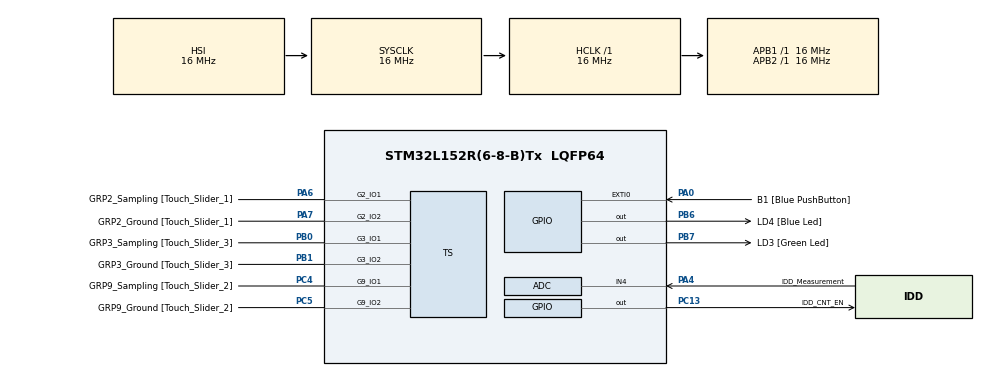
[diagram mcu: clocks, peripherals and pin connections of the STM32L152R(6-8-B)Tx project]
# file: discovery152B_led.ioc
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ADC.Channel=ADC_CHANNEL_4
ADC.Channel-0\#ChannelRegularConversion=ADC_CHANNEL_4
ADC.Channel-IN4=ADC_CHANNEL_4
ADC.ExternalTrigConv=ADC_EXTERNALTRIGCONV_T2_CC3
ADC.ExternalTrigConv-0\#ChannelRegularConversion=ADC_SOFTWARE_START
ADC.ExternalTrigConvEdge=ADC_EXTERNALTRIGCONVEDGE_RISING
ADC.Rank-0\#ChannelRegularConversion=1
ADC.SamplingTime-0\#ChannelRegularConversion=ADC_SAMPLETIME_4CYCLES
Dma.MEMTOMEM.0.Direction=DMA_MEMORY_TO_MEMORY
Dma.MEMTOMEM.0.Instance=DMA1_Channel1
Dma.MEMTOMEM.0.MemDataAlignment=DMA_MDATAALIGN_BYTE
Dma.MEMTOMEM.0.MemInc=DMA_MINC_ENABLE
Dma.MEMTOMEM.0.Mode=DMA_NORMAL
Dma.MEMTOMEM.0.PeriphDataAlignment=DMA_PDATAALIGN_BYTE
Dma.MEMTOMEM.0.PeriphInc=DMA_PINC_ENABLE
Dma.MEMTOMEM.0.Priority=DMA_PRIORITY_LOW
Dma.Request0=MEMTOMEM
Mcu.Family=STM32L1
Mcu.Name=STM32L152R(6-8-B)Tx
Mcu.Package=LQFP64
NVIC.PriorityGroup=NVIC_PRIORITYGROUP_0
PA0-WKUP1.GPIO_Label=B1 [Blue PushButton]
PA0-WKUP1.GPIO_ModeDefaultEXTI=GPIO_MODE_EVT_RISING
PA0-WKUP1.GPIO_PuPd=GPIO_NOPULL
PA0-WKUP1.Signal=GPXTI0
PA1.GPIO_Label=SEG0 [GH08172T_SEG0]
PA1.GPIO_Mode=GPIO_MODE_AF_PP
PA1.GPIO_PuPd=GPIO_NOPULL
PA1.GPIO_Speed=GPIO_SPEED_FREQ_LOW
PA1.Signal=LCD_SEG0
PA10.GPIO_Label=COM2 [GH08172T_COM2]
PA10.GPIO_Mode=GPIO_MODE_AF_PP
PA10.GPIO_PuPd=GPIO_NOPULL
PA10.GPIO_Speed=GPIO_SPEED_FREQ_LOW
PA10.Signal=LCD_COM2
PA13.GPIO_Label=SWDIO
PA13.Mode=Serial_Wire
PA13.Signal=SYS_JTMS-SWDIO
PA14.GPIO_Label=SWCLK
PA14.Mode=Serial_Wire
PA14.Signal=SYS_JTCK-SWCLK
PA15.GPIO_Label=SEG12 [GH08172T_SEG12]
PA15.GPIO_Mode=GPIO_MODE_AF_PP
PA15.GPIO_PuPd=GPIO_NOPULL
PA15.GPIO_Speed=GPIO_SPEED_FREQ_LOW
PA15.Signal=LCD_SEG17
PA2.GPIO_Label=SEG1 [GH08172T_SEG1]
PA2.GPIO_Mode=GPIO_MODE_AF_PP
PA2.GPIO_PuPd=GPIO_NOPULL
PA2.GPIO_Speed=GPIO_SPEED_FREQ_LOW
PA2.Signal=LCD_SEG1
PA3.GPIO_Label=SEG2 [GH08172T_SEG2]
PA3.GPIO_Mode=GPIO_MODE_AF_PP
PA3.GPIO_PuPd=GPIO_NOPULL
PA3.GPIO_Speed=GPIO_SPEED_FREQ_LOW
PA3.Signal=LCD_SEG2
PA4.GPIO_Label=IDD_Measurement
PA4.GPIO_Mode=GPIO_MODE_ANALOG
PA4.GPIO_PuPd=GPIO_NOPULL
PA4.Mode=IN4
PA4.Signal=ADC_IN4
PA6.GPIO_Label=GRP2_Sampling [Touch_Slider_1]
PA6.Mode=G2_IO1-Sampling
PA6.Signal=TS_G2_IO1
PA7.GPIO_Label=GRP2_Ground [Touch_Slider_1]
PA7.Mode=G2_IO2-Channel
PA7.Signal=TS_G2_IO2
PA8.GPIO_Label=COM0 [GH08172T_COM0]
PA8.GPIO_Mode=GPIO_MODE_AF_PP
PA8.GPIO_PuPd=GPIO_NOPULL
PA8.GPIO_Speed=GPIO_SPEED_FREQ_LOW
PA8.Signal=LCD_COM0
PA9.GPIO_Label=COM1 [GH08172T_COM1]
PA9.GPIO_Mode=GPIO_MODE_AF_PP
PA9.GPIO_PuPd=GPIO_NOPULL
PA9.GPIO_Speed=GPIO_SPEED_FREQ_LOW
PA9.Signal=LCD_COM1
PB0.GPIO_Label=GRP3_Sampling [Touch_Slider_3]
PB0.Mode=G3_IO1-Sampling
PB0.Signal=TS_G3_IO1
PB1.GPIO_Label=GRP3_Ground [Touch_Slider_3]
PB1.Mode=G3_IO2-Channel
PB1.Signal=TS_G3_IO2
PB10.GPIO_Label=SEG6 [GH08172T_SEG6]
PB10.GPIO_Mode=GPIO_MODE_AF_PP
PB10.GPIO_PuPd=GPIO_NOPULL
PB10.GPIO_Speed=GPIO_SPEED_FREQ_LOW
PB10.Signal=LCD_SEG10
PB11.GPIO_Label=SEG7 [GH08172T_SEG7]
PB11.GPIO_Mode=GPIO_MODE_AF_PP
PB11.GPIO_PuPd=GPIO_NOPULL
PB11.GPIO_Speed=GPIO_SPEED_FREQ_LOW
PB11.Signal=LCD_SEG11
PB12.GPIO_Label=SEG8 [GH08172T_SEG8]
PB12.GPIO_Mode=GPIO_MODE_AF_PP
PB12.GPIO_PuPd=GPIO_NOPULL
PB12.GPIO_Speed=GPIO_SPEED_FREQ_LOW
PB12.Signal=LCD_SEG12
PB13.GPIO_Label=SEG9 [GH08172T_SEG9]
PB13.GPIO_Mode=GPIO_MODE_AF_PP
PB13.GPIO_PuPd=GPIO_NOPULL
PB13.GPIO_Speed=GPIO_SPEED_FREQ_LOW
PB13.Signal=LCD_SEG13
PB14.GPIO_Label=SEG10 [GH08172T_SEG10]
PB14.GPIO_Mode=GPIO_MODE_AF_PP
PB14.GPIO_PuPd=GPIO_NOPULL
PB14.GPIO_Speed=GPIO_SPEED_FREQ_LOW
PB14.Signal=LCD_SEG14
PB15.GPIO_Label=SEG11 [GH08172T_SEG11]
PB15.GPIO_Mode=GPIO_MODE_AF_PP
PB15.GPIO_PuPd=GPIO_NOPULL
PB15.GPIO_Speed=GPIO_SPEED_FREQ_LOW
PB15.Signal=LCD_SEG15
PB3.GPIO_Label=SEG3 [GH08172T_SEG3]
PB3.GPIO_Mode=GPIO_MODE_AF_PP
PB3.GPIO_PuPd=GPIO_NOPULL
PB3.GPIO_Speed=GPIO_SPEED_FREQ_LOW
PB3.Signal=LCD_SEG7
PB4.GPIO_Label=SEG4 [GH08172T_SEG4]
PB4.GPIO_Mode=GPIO_MODE_AF_PP
PB4.GPIO_PuPd=GPIO_NOPULL
PB4.GPIO_Speed=GPIO_SPEED_FREQ_LOW
PB4.Signal=LCD_SEG8
PB5.GPIO_Label=SEG5 [GH08172T_SEG5]
PB5.GPIO_Mode=GPIO_MODE_AF_PP
PB5.GPIO_PuPd=GPIO_NOPULL
PB5.GPIO_Speed=GPIO_SPEED_FREQ_LOW
PB5.Signal=LCD_SEG9
PB6.GPIO_Label=LD4 [Blue Led]
PB6.GPIO_ModeDefaultOutputPP=GPIO_MODE_OUTPUT_PP
PB6.GPIO_PuPd=GPIO_NOPULL
PB6.GPIO_Speed=GPIO_SPEED_FREQ_LOW
PB6.Signal=GPIO_Output
PB7.GPIO_Label=LD3 [Green Led]
PB7.GPIO_ModeDefaultOutputPP=GPIO_MODE_OUTPUT_PP
PB7.GPIO_PuPd=GPIO_NOPULL
PB7.GPIO_Speed=GPIO_SPEED_FREQ_LOW
PB7.Signal=GPIO_Output
PB8.GPIO_Label=SEG13 [GH08172T_SEG13]
PB8.GPIO_Mode=GPIO_MODE_AF_PP
PB8.GPIO_PuPd=GPIO_NOPULL
PB8.GPIO_Speed=GPIO_SPEED_FREQ_LOW
PB8.Signal=LCD_SEG16
PB9.GPIO_Label=COM3 [GH08172T_COM3]
PB9.GPIO_Mode=GPIO_MODE_AF_PP
PB9.GPIO_PuPd=GPIO_NOPULL
PB9.GPIO_Speed=GPIO_SPEED_FREQ_LOW
PB9.Signal=LCD_COM3
PC0.GPIO_Label=SEG14 [GH08172T_SEG14]
PC0.GPIO_Mode=GPIO_MODE_AF_PP
PC0.GPIO_PuPd=GPIO_NOPULL
PC0.GPIO_Speed=GPIO_SPEED_FREQ_LOW
PC0.Signal=LCD_SEG18
PC1.GPIO_Label=SEG15 [GH08172T_SEG15]
PC1.GPIO_Mode=GPIO_MODE_AF_PP
PC1.GPIO_PuPd=GPIO_NOPULL
PC1.GPIO_Speed=GPIO_SPEED_FREQ_LOW
PC1.Signal=LCD_SEG19
PC10.GPIO_Label=SEG22 [GH08172T_SEG22]
PC10.GPIO_Mode=GPIO_MODE_AF_PP
PC10.GPIO_PuPd=GPIO_NOPULL
PC10.GPIO_Speed=GPIO_SPEED_FREQ_LOW
PC10.Signal=LCD_SEG28
PC11.GPIO_Label=SEG23 [GH08172T_SEG23]
PC11.GPIO_Mode=GPIO_MODE_AF_PP
PC11.GPIO_PuPd=GPIO_NOPULL
PC11.GPIO_Speed=GPIO_SPEED_FREQ_LOW
PC11.Signal=LCD_SEG29
PC13-WKUP2.GPIO_Label=IDD_CNT_EN
PC13-WKUP2.Signal=GPIO_Output
PC14-OSC32_IN.GPIO_Label=PC14-OSC32_IN
PC14-OSC32_IN.Mode=LSE-External-Oscillator
PC14-OSC32_IN.Signal=RCC_OSC32_IN
PC15-OSC32_OUT.GPIO_Label=PC15-OSC32_OUT
PC15-OSC32_OUT.Mode=LSE-External-Oscillator
PC15-OSC32_OUT.Signal=RCC_OSC32_OUT
PC2.GPIO_Label=SEG16 [GH08172T_SEG16]
PC2.GPIO_Mode=GPIO_MODE_AF_PP
PC2.GPIO_PuPd=GPIO_NOPULL
PC2.GPIO_Speed=GPIO_SPEED_FREQ_LOW
PC2.Signal=LCD_SEG20
PC3.GPIO_Label=SEG17 [GH08172T_SEG17]
PC3.GPIO_Mode=GPIO_MODE_AF_PP
PC3.GPIO_PuPd=GPIO_NOPULL
PC3.GPIO_Speed=GPIO_SPEED_FREQ_LOW
PC3.Signal=LCD_SEG21
PC4.GPIO_Label=GRP9_Sampling [Touch_Slider_2]
PC4.Mode=G9_IO1-Sampling
PC4.Signal=TS_G9_IO1
PC5.GPIO_Label=GRP9_Ground [Touch_Slider_2]
PC5.Mode=G9_IO2-Channel
PC5.Signal=TS_G9_IO2
PC6.GPIO_Label=SEG18 [GH08172T_SEG18]
PC6.GPIO_Mode=GPIO_MODE_AF_PP
PC6.GPIO_PuPd=GPIO_NOPULL
PC6.GPIO_Speed=GPIO_SPEED_FREQ_LOW
PC6.Signal=LCD_SEG24
PC7.GPIO_Label=SEG19 [GH08172T_SEG19]
PC7.GPIO_Mode=GPIO_MODE_AF_PP
PC7.GPIO_PuPd=GPIO_NOPULL
PC7.GPIO_Speed=GPIO_SPEED_FREQ_LOW
PC7.Signal=LCD_SEG25
PC8.GPIO_Label=SEG20 [GH08172T_SEG20]
PC8.GPIO_Mode=GPIO_MODE_AF_PP
PC8.GPIO_PuPd=GPIO_NOPULL
PC8.GPIO_Speed=GPIO_SPEED_FREQ_LOW
PC8.Signal=LCD_SEG26
PC9.GPIO_Label=SEG21 [GH08172T_SEG21]
PC9.GPIO_Mode=GPIO_MODE_AF_PP
PC9.GPIO_PuPd=GPIO_NOPULL
PC9.GPIO_Speed=GPIO_SPEED_FREQ_LOW
PC9.Signal=LCD_SEG27
PH0-OSC_IN.Mode=HSE-External-Oscillator
PH0-OSC_IN.Signal=RCC_OSC_IN
PH1-OSC_OUT.Mode=HSE-External-Oscillator
PH1-OSC_OUT.Signal=RCC_OSC_OUT
ProjectManager.HeapSize=0x200
ProjectManager.StackSize=0x400
ProjectManager.TargetToolchain=Makefile
RCC.48MHZClocksFreq_Value=48000000
RCC.AHBFreq_Value=16000000
RCC.APB1Freq_Value=16000000
RCC.APB1TimFreq_Value=16000000
RCC.APB2Freq_Value=16000000
RCC.APB2TimFreq_Value=16000000
RCC.HCLKFreq_Value=16000000
RCC.HSE_VALUE=8000000
RCC.HSI_VALUE=16000000
RCC.MSI_VALUE=2097000
RCC.PLLDIV=RCC_PLL_DIV3
RCC.PLLMUL=RCC_PLL_MUL6
RCC.RTCClockSelectionVirtual=RCC_RTCCLKSOURCE_LSE
RCC.SYSCLKFreq_VALUE=16000000
RCC.SYSCLKSource=RCC_SYSCLKSOURCE_HSI
RCC.USBOutput=48000000
RCC.VCOOutputFreq_Value=96000000
TS.SamplingIOs-G2_IO1-Sampling=TSC_GROUP2_IO1
TS.SamplingIOs-G3_IO1-Sampling=TSC_GROUP3_IO1
TS.SamplingIOs-G9_IO1-Sampling=TSC_GROUP9_IO1
board=STM32L-DISCOVERY

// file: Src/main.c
/* USER CODE BEGIN Header */
/**
  ******************************************************************************
  * @file           : main.c
  * @brief          : Main program body
  ******************************************************************************
  * @attention
  *
  * <h2><center>&copy; Copyright (c) 2020 STMicroelectronics.
  * All rights reserved.</center></h2>
  *
  * This software component is licensed by ST under BSD 3-Clause license,
  * the "License"; You may not use this file except in compliance with the
  * License. You may obtain a copy of the License at:
  *                        opensource.org/licenses/BSD-3-Clause
  *
  ******************************************************************************
  */
/* USER CODE END Header */

#include "main.h"

ADC_HandleTypeDef hadc;

DMA_HandleTypeDef hdma_memtomem_dma1_channel1;
/* USER CODE BEGIN PV */

static uint8_t ToggleLed;
/* USER CODE END PV */

void SystemClock_Config(void);
static void MX_GPIO_Init(void);
static void MX_DMA_Init(void);
static void MX_ADC_Init(void);
static void MX_TS_Init(void);
/* USER CODE BEGIN PFP */
void LED_ChangeRealize(void);
/* USER CODE END PFP */

/* USER CODE BEGIN 0 */

void LED_SetToChange(void)
{
    ToggleLed = 1;

}
void LED_ChangeRealize(void)
{

      HAL_GPIO_TogglePin(LD4_GPIO_Port, LD4_Pin);
      HAL_GPIO_TogglePin(LD3_GPIO_Port, LD3_Pin);
      ToggleLed=0;

}
/* USER CODE END 0 */

int main(void)
{

  /* MCU Configuration--------------------------------------------------------*/

  /* Reset of all peripherals, Initializes the Flash interface and the Systick. */
  HAL_Init();

  /* Configure the system clock */
  SystemClock_Config();

  /* Initialize all configured peripherals */
  MX_GPIO_Init();
  MX_DMA_Init();
  MX_ADC_Init();
  MX_TS_Init();

  /* Infinite loop */
  /* USER CODE BEGIN WHILE */
 HAL_GPIO_WritePin(LD4_GPIO_Port,LD4_Pin, GPIO_PIN_SET);
 HAL_GPIO_WritePin(LD3_GPIO_Port,LD3_Pin, GPIO_PIN_RESET);
  while (1)
  {
    /* USER CODE END WHILE */
      if (ToggleLed)
          LED_ChangeRealize();

  }
}

void SystemClock_Config(void)
{
  RCC_OscInitTypeDef RCC_OscInitStruct = {0};
  RCC_ClkInitTypeDef RCC_ClkInitStruct = {0};

  /** Configure the main internal regulator output voltage
  */
  __HAL_PWR_VOLTAGESCALING_CONFIG(PWR_REGULATOR_VOLTAGE_SCALE1);
  /** Initializes the CPU, AHB and APB busses clocks
  */
  RCC_OscInitStruct.OscillatorType = RCC_OSCILLATORTYPE_HSI;
  RCC_OscInitStruct.HSIState = RCC_HSI_ON;
  RCC_OscInitStruct.HSICalibrationValue = RCC_HSICALIBRATION_DEFAULT;
  RCC_OscInitStruct.PLL.PLLState = RCC_PLL_NONE;
  if (HAL_RCC_OscConfig(&RCC_OscInitStruct) != HAL_OK)
  {
    Error_Handler();
  }
  /** Initializes the CPU, AHB and APB busses clocks
  */
  RCC_ClkInitStruct.ClockType = RCC_CLOCKTYPE_HCLK|RCC_CLOCKTYPE_SYSCLK
                              |RCC_CLOCKTYPE_PCLK1|RCC_CLOCKTYPE_PCLK2;
  RCC_ClkInitStruct.SYSCLKSource = RCC_SYSCLKSOURCE_HSI;
  RCC_ClkInitStruct.AHBCLKDivider = RCC_SYSCLK_DIV1;
  RCC_ClkInitStruct.APB1CLKDivider = RCC_HCLK_DIV1;
  RCC_ClkInitStruct.APB2CLKDivider = RCC_HCLK_DIV1;

  if (HAL_RCC_ClockConfig(&RCC_ClkInitStruct, FLASH_LATENCY_0) != HAL_OK)
  {
    Error_Handler();
  }
}

static void MX_ADC_Init(void)
{

  ADC_ChannelConfTypeDef sConfig = {0};

  /** Configure the global features of the ADC (Clock, Resolution, Data Alignment and number of conversion)
  */
  hadc.Instance = ADC1;
  hadc.Init.ClockPrescaler = ADC_CLOCK_ASYNC_DIV1;
  hadc.Init.Resolution = ADC_RESOLUTION_12B;
  hadc.Init.DataAlign = ADC_DATAALIGN_RIGHT;
  hadc.Init.ScanConvMode = ADC_SCAN_DISABLE;
  hadc.Init.EOCSelection = ADC_EOC_SEQ_CONV;
  hadc.Init.LowPowerAutoWait = ADC_AUTOWAIT_DISABLE;
  hadc.Init.LowPowerAutoPowerOff = ADC_AUTOPOWEROFF_DISABLE;
  hadc.Init.ChannelsBank = ADC_CHANNELS_BANK_A;
  hadc.Init.ContinuousConvMode = DISABLE;
  hadc.Init.NbrOfConversion = 1;
  hadc.Init.DiscontinuousConvMode = DISABLE;
  hadc.Init.ExternalTrigConv = ADC_EXTERNALTRIGCONV_T2_CC3;
  hadc.Init.ExternalTrigConvEdge = ADC_EXTERNALTRIGCONVEDGE_RISING;
  hadc.Init.DMAContinuousRequests = DISABLE;
  if (HAL_ADC_Init(&hadc) != HAL_OK)
  {
    Error_Handler();
  }
  /** Configure for the selected ADC regular channel its corresponding rank in the sequencer and its sample time.
  */
  sConfig.Channel = ADC_CHANNEL_4;
  sConfig.Rank = ADC_REGULAR_RANK_1;
  sConfig.SamplingTime = ADC_SAMPLETIME_4CYCLES;
  if (HAL_ADC_ConfigChannel(&hadc, &sConfig) != HAL_OK)
  {
    Error_Handler();
  }

}

static void MX_TS_Init(void)
{

}

static void MX_DMA_Init(void)
{

  /* DMA controller clock enable */
  __HAL_RCC_DMA1_CLK_ENABLE();

  /* Configure DMA request hdma_memtomem_dma1_channel1 on DMA1_Channel1 */
  hdma_memtomem_dma1_channel1.Instance = DMA1_Channel1;
  hdma_memtomem_dma1_channel1.Init.Direction = DMA_MEMORY_TO_MEMORY;
  hdma_memtomem_dma1_channel1.Init.PeriphInc = DMA_PINC_ENABLE;
  hdma_memtomem_dma1_channel1.Init.MemInc = DMA_MINC_ENABLE;
  hdma_memtomem_dma1_channel1.Init.PeriphDataAlignment = DMA_PDATAALIGN_BYTE;
  hdma_memtomem_dma1_channel1.Init.MemDataAlignment = DMA_MDATAALIGN_BYTE;
  hdma_memtomem_dma1_channel1.Init.Mode = DMA_NORMAL;
  hdma_memtomem_dma1_channel1.Init.Priority = DMA_PRIORITY_LOW;
  if (HAL_DMA_Init(&hdma_memtomem_dma1_channel1) != HAL_OK)
  {
    Error_Handler( );
  }

}

static void MX_GPIO_Init(void)
{
  GPIO_InitTypeDef GPIO_InitStruct = {0};

  /* GPIO Ports Clock Enable */
  __HAL_RCC_GPIOC_CLK_ENABLE();
  __HAL_RCC_GPIOH_CLK_ENABLE();
  __HAL_RCC_GPIOA_CLK_ENABLE();
  __HAL_RCC_GPIOB_CLK_ENABLE();

  /*Configure GPIO pin Output Level */
  HAL_GPIO_WritePin(IDD_CNT_EN_GPIO_Port, IDD_CNT_EN_Pin, GPIO_PIN_RESET);

  /*Configure GPIO pin Output Level */
  HAL_GPIO_WritePin(GPIOB, LD4_Pin|LD3_Pin, GPIO_PIN_RESET);

  /*Configure GPIO pin : IDD_CNT_EN_Pin */
  GPIO_InitStruct.Pin = IDD_CNT_EN_Pin;
  GPIO_InitStruct.Mode = GPIO_MODE_OUTPUT_PP;
  GPIO_InitStruct.Pull = GPIO_NOPULL;
  GPIO_InitStruct.Speed = GPIO_SPEED_FREQ_LOW;
  HAL_GPIO_Init(IDD_CNT_EN_GPIO_Port, &GPIO_InitStruct);

  /*Configure GPIO pins : SEG14_Pin SEG15_Pin SEG16_Pin SEG17_Pin
                           SEG18_Pin SEG19_Pin SEG20_Pin SEG21_Pin
                           SEG22_Pin SEG23_Pin */
  GPIO_InitStruct.Pin = SEG14_Pin|SEG15_Pin|SEG16_Pin|SEG17_Pin
                          |SEG18_Pin|SEG19_Pin|SEG20_Pin|SEG21_Pin
                          |SEG22_Pin|SEG23_Pin;
  GPIO_InitStruct.Mode = GPIO_MODE_AF_PP;
  GPIO_InitStruct.Pull = GPIO_NOPULL;
  GPIO_InitStruct.Speed = GPIO_SPEED_FREQ_LOW;
  GPIO_InitStruct.Alternate = GPIO_AF11_LCD;
  HAL_GPIO_Init(GPIOC, &GPIO_InitStruct);

  /*Configure GPIO pin : B1_Pin */
  GPIO_InitStruct.Pin = B1_Pin;
  GPIO_InitStruct.Mode = GPIO_MODE_EVT_RISING;
  GPIO_InitStruct.Pull = GPIO_NOPULL;
  HAL_GPIO_Init(B1_GPIO_Port, &GPIO_InitStruct);

  /*Configure GPIO pins : SEG0_Pin SEG1_Pin SEG2_Pin COM0_Pin
                           COM1_Pin COM2_Pin SEG12_Pin */
  GPIO_InitStruct.Pin = SEG0_Pin|SEG1_Pin|SEG2_Pin|COM0_Pin
                          |COM1_Pin|COM2_Pin|SEG12_Pin;
  GPIO_InitStruct.Mode = GPIO_MODE_AF_PP;
  GPIO_InitStruct.Pull = GPIO_NOPULL;
  GPIO_InitStruct.Speed = GPIO_SPEED_FREQ_LOW;
  GPIO_InitStruct.Alternate = GPIO_AF11_LCD;
  HAL_GPIO_Init(GPIOA, &GPIO_InitStruct);

  /*Configure GPIO pins : SEG6_Pin SEG7_Pin SEG8_Pin SEG9_Pin
                           SEG10_Pin SEG11_Pin SEG3_Pin SEG4_Pin
                           SEG5_Pin SEG13_Pin COM3_Pin */
  GPIO_InitStruct.Pin = SEG6_Pin|SEG7_Pin|SEG8_Pin|SEG9_Pin
                          |SEG10_Pin|SEG11_Pin|SEG3_Pin|SEG4_Pin
                          |SEG5_Pin|SEG13_Pin|COM3_Pin;
  GPIO_InitStruct.Mode = GPIO_MODE_AF_PP;
  GPIO_InitStruct.Pull = GPIO_NOPULL;
  GPIO_InitStruct.Speed = GPIO_SPEED_FREQ_LOW;
  GPIO_InitStruct.Alternate = GPIO_AF11_LCD;
  HAL_GPIO_Init(GPIOB, &GPIO_InitStruct);

  /*Configure GPIO pins : LD4_Pin LD3_Pin */
  GPIO_InitStruct.Pin = LD4_Pin|LD3_Pin;
  GPIO_InitStruct.Mode = GPIO_MODE_OUTPUT_PP;
  GPIO_InitStruct.Pull = GPIO_NOPULL;
  GPIO_InitStruct.Speed = GPIO_SPEED_FREQ_LOW;
  HAL_GPIO_Init(GPIOB, &GPIO_InitStruct);

}

void Error_Handler(void)
{
}

/************************ (C) COPYRIGHT STMicroelectronics *****END OF FILE****/
